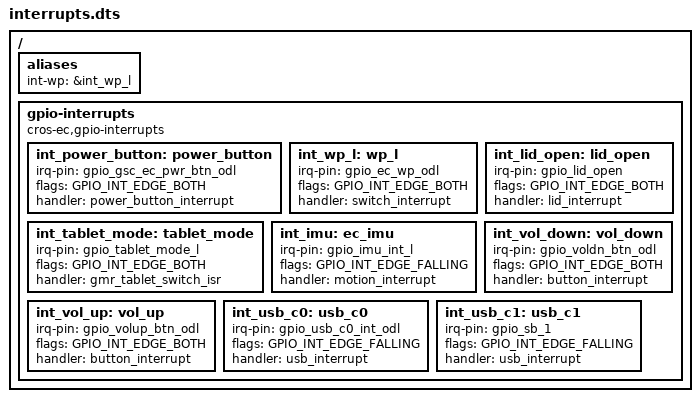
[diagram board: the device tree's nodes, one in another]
/* Copyright 2022 The ChromiumOS Authors
 * Use of this source code is governed by a BSD-style license that can be
 * found in the LICENSE file.
 */

/ {
	aliases {
		int-wp = &int_wp_l;
	};

	gpio-interrupts {
		compatible = "cros-ec,gpio-interrupts";

		int_power_button: power_button {
			irq-pin = <&gpio_gsc_ec_pwr_btn_odl>;
			flags = <GPIO_INT_EDGE_BOTH>;
			handler = "power_button_interrupt";
		};
		int_wp_l: wp_l {
			irq-pin = <&gpio_ec_wp_odl>;
			flags = <GPIO_INT_EDGE_BOTH>;
			handler = "switch_interrupt";
		};
		int_lid_open: lid_open {
			irq-pin = <&gpio_lid_open>;
			flags = <GPIO_INT_EDGE_BOTH>;
			handler = "lid_interrupt";
		};
		int_tablet_mode: tablet_mode {
			irq-pin = <&gpio_tablet_mode_l>;
			flags = <GPIO_INT_EDGE_BOTH>;
			handler = "gmr_tablet_switch_isr";
		};
		int_imu: ec_imu {
			irq-pin = <&gpio_imu_int_l>;
			flags = <GPIO_INT_EDGE_FALLING>;
			handler = "motion_interrupt";
		};
		int_vol_down: vol_down {
			irq-pin = <&gpio_voldn_btn_odl>;
			flags = <GPIO_INT_EDGE_BOTH>;
			handler = "button_interrupt";
		};
		int_vol_up: vol_up {
			irq-pin = <&gpio_volup_btn_odl>;
			flags = <GPIO_INT_EDGE_BOTH>;
			handler = "button_interrupt";
		};
		int_usb_c0: usb_c0 {
			irq-pin = <&gpio_usb_c0_int_odl>;
			flags = <GPIO_INT_EDGE_FALLING>;
			handler = "usb_interrupt";
		};
		int_usb_c1: usb_c1 {
			irq-pin = <&gpio_sb_1>;
			flags = <GPIO_INT_EDGE_FALLING>;
			handler = "usb_interrupt";
		};
	};
};
